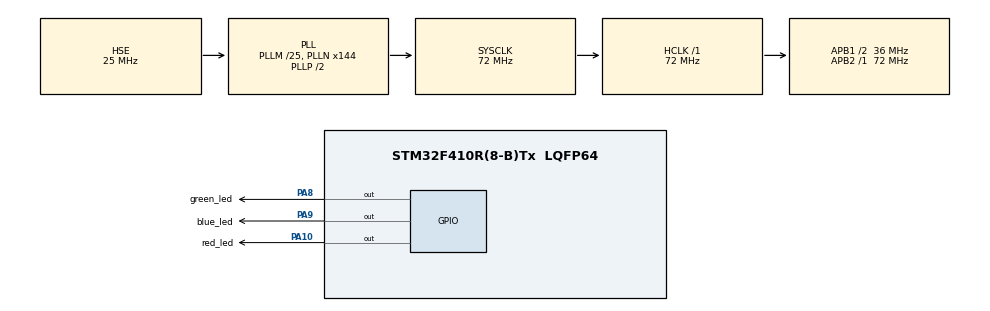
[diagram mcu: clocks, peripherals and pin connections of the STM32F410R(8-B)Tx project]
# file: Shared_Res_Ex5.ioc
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FREERTOS.Tasks01=defaultTask,24,128,StartDefaultTask,Default,NULL,Dynamic,NULL,NULL;GreenLed,24,128,GreenLedTask,Default,NULL,Dynamic,NULL,NULL;RedLed,40,128,RedLedTask,Default,NULL,Dynamic,NULL,NULL
FREERTOS.configTOTAL_HEAP_SIZE=3600
Mcu.Family=STM32F4
Mcu.Name=STM32F410R(8-B)Tx
Mcu.Package=LQFP64
NVIC.PriorityGroup=NVIC_PRIORITYGROUP_4
PA10.GPIO_Label=red_led
PA10.Signal=GPIO_Output
PA13.Mode=Serial_Wire
PA13.Signal=SYS_JTMS-SWDIO
PA14.Mode=Serial_Wire
PA14.Signal=SYS_JTCK-SWCLK
PA8.GPIO_Label=green_led
PA8.Signal=GPIO_Output
PA9.GPIO_Label=blue_led
PA9.Signal=GPIO_Output
PH0\ -\ OSC_IN.Mode=HSE-External-Oscillator
PH0\ -\ OSC_IN.Signal=RCC_OSC_IN
PH1\ -\ OSC_OUT.Mode=HSE-External-Oscillator
PH1\ -\ OSC_OUT.Signal=RCC_OSC_OUT
ProjectManager.HeapSize=0x200
ProjectManager.StackSize=0x400
ProjectManager.TargetToolchain=STM32CubeIDE
RCC.48MHZClocksFreq_Value=36000000
RCC.AHBFreq_Value=72000000
RCC.APB1CLKDivider=RCC_HCLK_DIV2
RCC.APB1Freq_Value=36000000
RCC.APB1TimFreq_Value=72000000
RCC.APB2Freq_Value=72000000
RCC.APB2TimFreq_Value=72000000
RCC.CortexFreq_Value=72000000
RCC.HCLKFreq_Value=72000000
RCC.HSE_VALUE=25000000
RCC.HSI_VALUE=16000000
RCC.LSE_VALUE=32768
RCC.PLLM=25
RCC.PLLN=144
RCC.PLLSourceVirtual=RCC_PLLSOURCE_HSE
RCC.SYSCLKFreq_VALUE=72000000
RCC.SYSCLKSource=RCC_SYSCLKSOURCE_PLLCLK
RCC.VCOOutputFreq_Value=144000000
VP_FREERTOS_VS_CMSIS_V2.Mode=CMSIS_V2
board=custom

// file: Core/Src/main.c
/* USER CODE BEGIN Header */
/**
  ******************************************************************************
  * @file           : main.c
  * @brief          : Main program body
  ******************************************************************************
  * @attention
  *
  * Copyright (c) 2024 STMicroelectronics.
  * All rights reserved.
  *
  * This software is licensed under terms that can be found in the LICENSE file
  * in the root directory of this software component.
  * If no LICENSE file comes with this software, it is provided AS-IS.
  *
  ******************************************************************************
  */
/* USER CODE END Header */
#include "main.h"
#include "cmsis_os.h"

/* Definitions for defaultTask */
osThreadId_t defaultTaskHandle;
const osThreadAttr_t defaultTask_attributes = {
  .name = "defaultTask",
  .stack_size = 128 * 4,
  .priority = (osPriority_t) osPriorityNormal,
};
/* Definitions for GreenLed */
osThreadId_t GreenLedHandle;
const osThreadAttr_t GreenLed_attributes = {
  .name = "GreenLed",
  .stack_size = 128 * 4,
  .priority = (osPriority_t) osPriorityNormal,
};
/* Definitions for RedLed */
osThreadId_t RedLedHandle;
const osThreadAttr_t RedLed_attributes = {
  .name = "RedLed",
  .stack_size = 128 * 4,
  .priority = (osPriority_t) osPriorityHigh,
};
/* USER CODE BEGIN PV */
volatile int StartFlag=1;
/* USER CODE END PV */

void SystemClock_Config(void);
static void MX_GPIO_Init(void);
void StartDefaultTask(void *argument);
void GreenLedTask(void *argument);
void RedLedTask(void *argument);

/* USER CODE BEGIN 0 */
void AccessSharedData(void) {
	if (StartFlag == 1) {
		StartFlag = 0; // Set StartFlag to Down (0)

		// Simulate read/write operations
		osDelay(500); // Simulating shared resource access delay

		StartFlag = 1; // Set StartFlag back to Up (1)
	} else {
		// Collision detected, turn on Blue LED
		HAL_GPIO_WritePin(GPIOA, blue_led_Pin, GPIO_PIN_SET);

		// Keep Blue LED on for 100 ms
		osDelay(100);
		HAL_GPIO_WritePin(GPIOA, blue_led_Pin, GPIO_PIN_RESET);
	}
}
/* USER CODE END 0 */

int main(void)
{

  /* MCU Configuration--------------------------------------------------------*/

  /* Reset of all peripherals, Initializes the Flash interface and the Systick. */
  HAL_Init();

  /* Configure the system clock */
  SystemClock_Config();

  /* Initialize all configured peripherals */
  MX_GPIO_Init();

  /* Init scheduler */
  osKernelInitialize();

  /* Create the thread(s) */
  /* creation of defaultTask */
  defaultTaskHandle = osThreadNew(StartDefaultTask, NULL, &defaultTask_attributes);

  /* creation of GreenLed */
  GreenLedHandle = osThreadNew(GreenLedTask, NULL, &GreenLed_attributes);

  /* creation of RedLed */
  RedLedHandle = osThreadNew(RedLedTask, NULL, &RedLed_attributes);

  /* Start scheduler */
  osKernelStart();

  /* We should never get here as control is now taken by the scheduler */

  /* Infinite loop */
  while (1)
  {

  }
}

void SystemClock_Config(void)
{
  RCC_OscInitTypeDef RCC_OscInitStruct = {0};
  RCC_ClkInitTypeDef RCC_ClkInitStruct = {0};

  /** Configure the main internal regulator output voltage
  */
  __HAL_RCC_PWR_CLK_ENABLE();
  __HAL_PWR_VOLTAGESCALING_CONFIG(PWR_REGULATOR_VOLTAGE_SCALE1);

  /** Initializes the RCC Oscillators according to the specified parameters
  * in the RCC_OscInitTypeDef structure.
  */
  RCC_OscInitStruct.OscillatorType = RCC_OSCILLATORTYPE_HSE;
  RCC_OscInitStruct.HSEState = RCC_HSE_ON;
  RCC_OscInitStruct.PLL.PLLState = RCC_PLL_ON;
  RCC_OscInitStruct.PLL.PLLSource = RCC_PLLSOURCE_HSE;
  RCC_OscInitStruct.PLL.PLLM = 25;
  RCC_OscInitStruct.PLL.PLLN = 144;
  RCC_OscInitStruct.PLL.PLLP = RCC_PLLP_DIV2;
  RCC_OscInitStruct.PLL.PLLQ = 4;
  RCC_OscInitStruct.PLL.PLLR = 2;
  if (HAL_RCC_OscConfig(&RCC_OscInitStruct) != HAL_OK)
  {
    Error_Handler();
  }

  /** Initializes the CPU, AHB and APB buses clocks
  */
  RCC_ClkInitStruct.ClockType = RCC_CLOCKTYPE_HCLK|RCC_CLOCKTYPE_SYSCLK
                              |RCC_CLOCKTYPE_PCLK1|RCC_CLOCKTYPE_PCLK2;
  RCC_ClkInitStruct.SYSCLKSource = RCC_SYSCLKSOURCE_PLLCLK;
  RCC_ClkInitStruct.AHBCLKDivider = RCC_SYSCLK_DIV1;
  RCC_ClkInitStruct.APB1CLKDivider = RCC_HCLK_DIV2;
  RCC_ClkInitStruct.APB2CLKDivider = RCC_HCLK_DIV1;

  if (HAL_RCC_ClockConfig(&RCC_ClkInitStruct, FLASH_LATENCY_2) != HAL_OK)
  {
    Error_Handler();
  }
}

static void MX_GPIO_Init(void)
{
  GPIO_InitTypeDef GPIO_InitStruct = {0};

  /* GPIO Ports Clock Enable */
  __HAL_RCC_GPIOH_CLK_ENABLE();
  __HAL_RCC_GPIOA_CLK_ENABLE();

  /*Configure GPIO pin Output Level */
  HAL_GPIO_WritePin(GPIOA, green_led_Pin|blue_led_Pin|red_led_Pin, GPIO_PIN_RESET);

  /*Configure GPIO pins : green_led_Pin blue_led_Pin red_led_Pin */
  GPIO_InitStruct.Pin = green_led_Pin|blue_led_Pin|red_led_Pin;
  GPIO_InitStruct.Mode = GPIO_MODE_OUTPUT_PP;
  GPIO_InitStruct.Pull = GPIO_NOPULL;
  GPIO_InitStruct.Speed = GPIO_SPEED_FREQ_LOW;
  HAL_GPIO_Init(GPIOA, &GPIO_InitStruct);

}

void StartDefaultTask(void *argument)
{
  for(;;)
  {
    osDelay(1);
  }
}

void GreenLedTask(void *argument)
{
  /* USER CODE BEGIN GreenLedTask */
  /* Infinite loop */
  for(;;)
  {
	  // Turn Green LED on
	  HAL_GPIO_WritePin(GPIOA, green_led_Pin, GPIO_PIN_SET);

	  // Access the shared data
	  AccessSharedData();

	  // Turn Green LED off
	  HAL_GPIO_WritePin(GPIOA, green_led_Pin, GPIO_PIN_RESET);

	  osDelay(500);
  }
  /* USER CODE END GreenLedTask */
}

void RedLedTask(void *argument)
{
  /* USER CODE BEGIN RedLedTask */
  /* Infinite loop */
  for(;;)
  {
	  // Turn Green LED on
	  HAL_GPIO_WritePin(GPIOA, red_led_Pin, GPIO_PIN_SET);

	  // Access the shared data
	  AccessSharedData();

	  // Turn Green LED off
	  HAL_GPIO_WritePin(GPIOA, red_led_Pin, GPIO_PIN_RESET);

	  osDelay(100);
  }
  /* USER CODE END RedLedTask */
}

void Error_Handler(void)
{
  __disable_irq();
  while (1)
  {
  }
}
